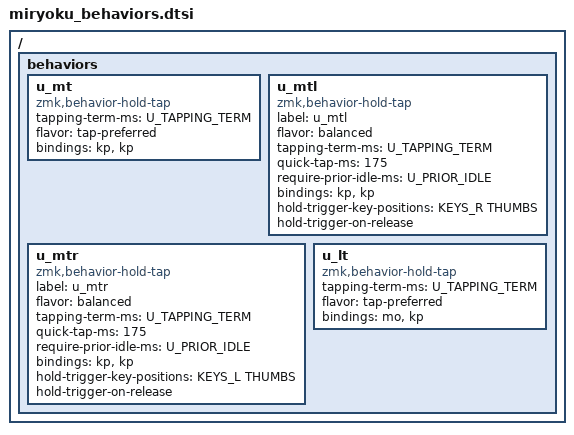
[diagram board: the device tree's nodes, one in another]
// Copyright 2022 Manna Harbour
// https://github.com/manna-harbour/miryoku

// Adv360 Pro physical key positions (binding index into the generated keymap,
// see MIRYOKU_LAYOUTMAPPING_ADV360PRO in custom_config.h). NOT the 36-key
// Miryoku layout - the number row, outer columns and inner thumb mods shift
// every index.
#define KEYS_L 15 16 17 18 19 \
               29 30 31 32 33 \
               47 48 49 50 51

#define KEYS_R 22 23 24 25 26 \
               40 41 42 43 44 \
               54 55 56 57 58

#define THUMBS 65 66 67 68 69 70

#define U_PRIOR_IDLE 110

/ {
  behaviors {
    u_mt: u_mt {
      compatible = "zmk,behavior-hold-tap";
      #binding-cells = <2>;
      tapping-term-ms = <U_TAPPING_TERM>;
      flavor = "tap-preferred";
      bindings = <&kp>, <&kp>;
    };

    // https://github.com/urob/zmk-config?tab=readme-ov-file#timeless-homerow-mods
    u_mtl: u_mtl {
        compatible = "zmk,behavior-hold-tap";
        label = "u_mtl";
        #binding-cells = <2>;
        flavor = "balanced";
        tapping-term-ms = <U_TAPPING_TERM>;
        quick-tap-ms = <175>;
        require-prior-idle-ms = <U_PRIOR_IDLE>;
        bindings = <&kp>, <&kp>;
        hold-trigger-key-positions = <KEYS_R THUMBS>;
        hold-trigger-on-release;
    };
    u_mtr: u_mtr {
        compatible = "zmk,behavior-hold-tap";
        label = "u_mtr";
        #binding-cells = <2>;
        flavor = "balanced";
        tapping-term-ms = <U_TAPPING_TERM>;
        quick-tap-ms = <175>;
        require-prior-idle-ms = <U_PRIOR_IDLE>;
        bindings = <&kp>, <&kp>;
        hold-trigger-key-positions = <KEYS_L THUMBS>;
        hold-trigger-on-release;
    };

    u_lt: u_lt {
      compatible = "zmk,behavior-hold-tap";
      #binding-cells = <2>;
      tapping-term-ms = <U_TAPPING_TERM>;
      flavor = "tap-preferred";
      bindings = <&mo>, <&kp>;
    };
  };
};
